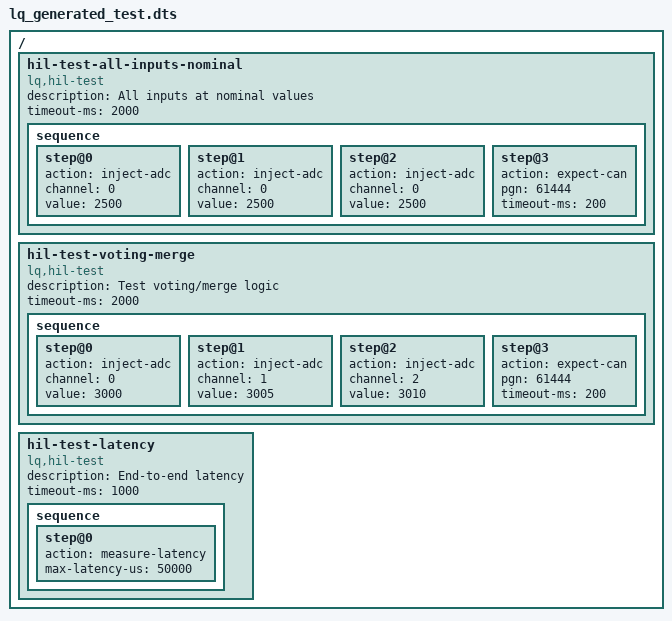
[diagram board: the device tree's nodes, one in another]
/*
 * AUTO-GENERATED HIL Tests
 * Generated from system DTS
 * DO NOT EDIT MANUALLY
 */

/ {
    hil-test-all-inputs-nominal {
        compatible = "lq,hil-test";
        description = "All inputs at nominal values";
        timeout-ms = <2000>;
        
        sequence {
            step@0 {
                action = "inject-adc";
                channel = <0>;
                value = <2500>;
            };
            step@1 {
                action = "inject-adc";
                channel = <0>;
                value = <2500>;
            };
            step@2 {
                action = "inject-adc";
                channel = <0>;
                value = <2500>;
            };
            step@3 {
                action = "expect-can";
                pgn = <61444>;
                timeout-ms = <200>;
            };
        };
    };

    hil-test-voting-merge {
        compatible = "lq,hil-test";
        description = "Test voting/merge logic";
        timeout-ms = <2000>;
        
        sequence {
            step@0 {
                action = "inject-adc";
                channel = <0>;
                value = <3000>;
            };
            step@1 {
                action = "inject-adc";
                channel = <1>;
                value = <3005>;
            };
            step@2 {
                action = "inject-adc";
                channel = <2>;
                value = <3010>;
            };
            step@3 {
                action = "expect-can";
                pgn = <61444>;
                timeout-ms = <200>;
            };
        };
    };

    hil-test-latency {
        compatible = "lq,hil-test";
        description = "End-to-end latency";
        timeout-ms = <1000>;
        
        sequence {
            step@0 {
                action = "measure-latency";
                max-latency-us = <50000>;  /* 50ms */
            };
        };
    };

};
